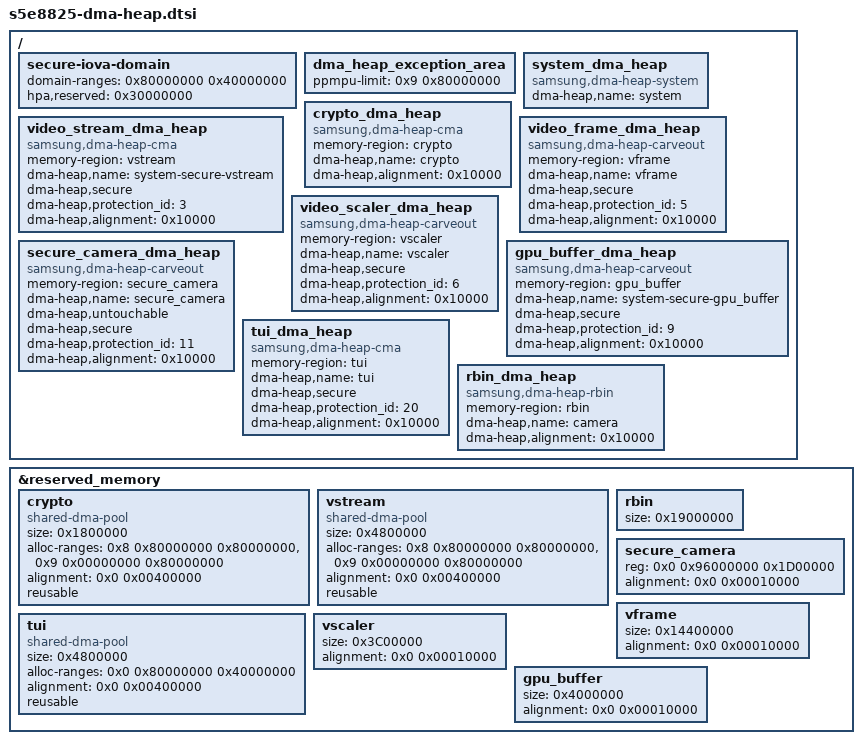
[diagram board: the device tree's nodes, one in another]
// SPDX-License-Identifier: GPL-2.0
/*
 * EXYNOS DMA HEAP device tree source for reserved-memory
 *
 * Copyright (c) 2021 Samsung Electronics Co., Ltd.
 */

/ {
	secure-iova-domain {
		#address-cells = <1>;
		#size-cells = <1>;
		domain-ranges = <0x80000000 0x40000000>;
		hpa,reserved = <0x30000000>;
	};

	dma_heap_exception_area {
		#address-cells = <2>;
		#size-cells = <1>;
		ppmpu-limit = <0x9 0x80000000>;
	};

	system_dma_heap {
		compatible = "samsung,dma-heap-system";
		dma-heap,name = "system";
	};

	crypto_dma_heap {
		compatible = "samsung,dma-heap-cma";
		memory-region = <&crypto>;
		dma-heap,name = "crypto";
		dma-heap,alignment = <0x10000>;
	};

	video_stream_dma_heap {
		compatible = "samsung,dma-heap-cma";
		memory-region = <&vstream>;
		dma-heap,name = "system-secure-vstream";
		dma-heap,secure;
		dma-heap,protection_id = <3>;
		dma-heap,alignment = <0x10000>;
	};

	video_frame_dma_heap {
		compatible = "samsung,dma-heap-carveout";
		memory-region = <&vframe>;
		dma-heap,name = "vframe";
		dma-heap,secure;
		dma-heap,protection_id = <5>;
		dma-heap,alignment = <0x10000>;
	};

	video_scaler_dma_heap {
		compatible = "samsung,dma-heap-carveout";
		memory-region = <&vscaler>;
		dma-heap,name = "vscaler";
		dma-heap,secure;
		dma-heap,protection_id = <6>;
		dma-heap,alignment = <0x10000>;
	};

	gpu_buffer_dma_heap {
		compatible = "samsung,dma-heap-carveout";
		memory-region = <&gpu_buffer>;
		dma-heap,name = "system-secure-gpu_buffer";
		dma-heap,secure;
		dma-heap,protection_id = <9>;
		dma-heap,alignment = <0x10000>;
	};

	secure_camera_dma_heap {
		compatible = "samsung,dma-heap-carveout";
		memory-region = <&secure_camera>;
		dma-heap,name = "secure_camera";
		dma-heap,untouchable;
		dma-heap,secure;
		dma-heap,protection_id = <11>;
		dma-heap,alignment = <0x10000>;
	};

	tui_dma_heap {
		compatible = "samsung,dma-heap-cma";
		memory-region = <&tui>;
		dma-heap,name = "tui";
		dma-heap,secure;
		dma-heap,protection_id = <20>;
		dma-heap,alignment = <0x10000>;
	};

	rbin_dma_heap {
		compatible = "samsung,dma-heap-rbin";
		memory-region = <&rbin>;
		dma-heap,name = "camera";
		dma-heap,alignment = <0x10000>;
	};
};

&reserved_memory {
	#address-cells = <2>;
	#size-cells = <1>;

	crypto: crypto {
		compatible = "shared-dma-pool";
		size = <0x1800000>;
		alloc-ranges =	<0x8 0x80000000 0x80000000>,
				<0x9 0x00000000 0x80000000>;
		alignment = <0x0 0x00400000>;
		reusable;
	};

	vstream: vstream {
		compatible = "shared-dma-pool";
		size = <0x4800000>;
		alloc-ranges =	<0x8 0x80000000 0x80000000>,
				<0x9 0x00000000 0x80000000>;
		alignment = <0x0 0x00400000>;
		reusable;
	};

	tui: tui {
		compatible = "shared-dma-pool";
		size = <0x4800000>;
		alloc-ranges = <0x0 0x80000000 0x40000000>;
		alignment = <0x0 0x00400000>;
		reusable;
	};

	rbin: rbin {
		size = <0x19000000>;
	};

	secure_camera: secure_camera {
		reg = <0x0 0x96000000 0x1D00000>;
		alignment = <0x0 0x00010000>;
	};

	vframe: vframe {
		size = <0x14400000>;
		alignment = <0x0 0x00010000>;
	};

	vscaler: vscaler {
		size = <0x3C00000>;
		alignment = <0x0 0x00010000>;
	};

	gpu_buffer: gpu_buffer {
		size = <0x4000000>;
		alignment = <0x0 0x00010000>;
	};
};
